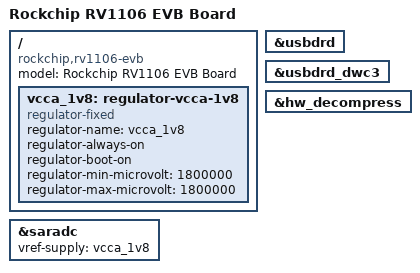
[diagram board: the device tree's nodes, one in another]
// SPDX-License-Identifier: (GPL-2.0+ OR MIT)
/*
 * Copyright (c) 2021 Fuzhou Rockchip Electronics Co., Ltd.
 */

/dts-v1/;

#include "rv1106.dtsi"
#include "rv1106-u-boot.dtsi"
#include <dt-bindings/input/input.h>

/ {
	model = "Rockchip RV1106 EVB Board";
	compatible = "rockchip,rv1106-evb", "rockchip,rv1106";

	vcca_1v8: regulator-vcca-1v8 {
        bootph-all;
		compatible = "regulator-fixed";
		regulator-name = "vcca_1v8";
		regulator-always-on;
		regulator-boot-on;
		regulator-min-microvolt = <1800000>;
		regulator-max-microvolt = <1800000>;
	};
};

&saradc {
    vref-supply = <&vcca_1v8>;
};

&usbdrd {
	status = "okay";
};

&usbdrd_dwc3 {
	status = "okay";
};

&hw_decompress {
	u-boot,dm-spl;
	status = "okay";
};
